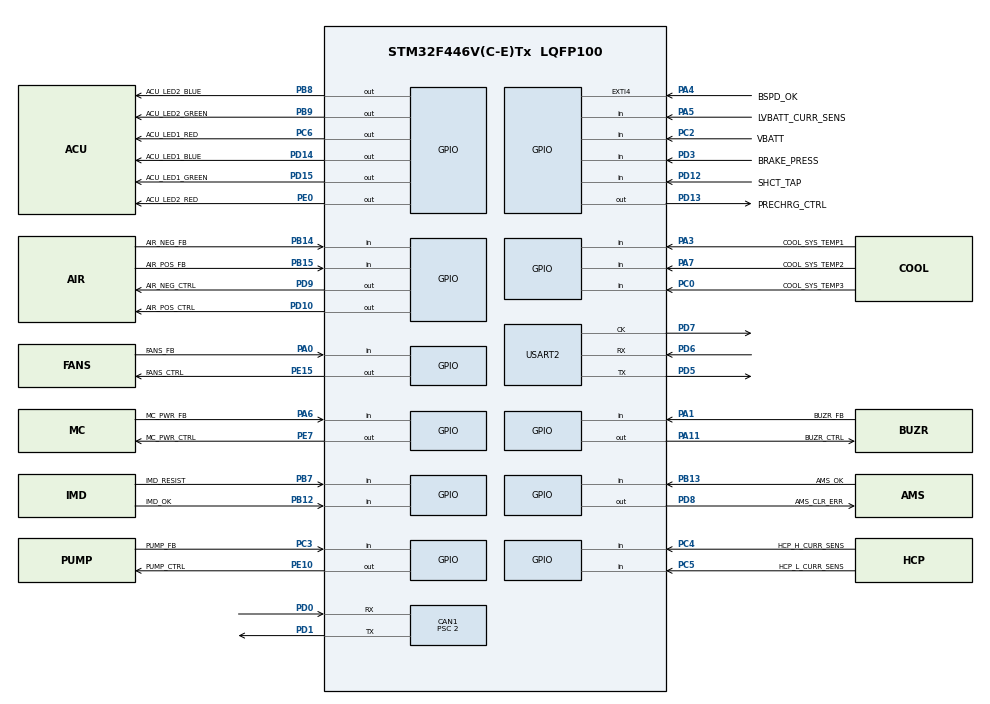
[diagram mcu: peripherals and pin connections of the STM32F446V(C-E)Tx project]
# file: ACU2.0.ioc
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CAN1.BS1=CAN_BS1_13TQ
CAN1.BS2=CAN_BS2_2TQ
CAN1.CalculateBaudRate=500000
CAN1.CalculateTimeBit=2000
CAN1.CalculateTimeQuantum=125.0
CAN1.Prescaler=2
FREERTOS.Events01=iwdgEventGroup,Dynamic,NULL
FREERTOS.INCLUDE_xTaskGetHandle=1
FREERTOS.Queues01=canRxPacketQueue,32,CAN_RxPacketTypeDef,0,Dynamic,NULL,NULL;canTxPacketQueue,32,CAN_TxPacketTypeDef,0,Dynamic,NULL,NULL;setCarStateQueue,32,uint8_t,0,Dynamic,NULL,NULL;bmsRxCanMsgQueue,16,CAN_RxPacketTypeDef,0,Dynamic,NULL,NULL;vcuCanCommsQueue,16,CAN_RxPacketTypeDef,0,Dynamic,NULL,NULL
FREERTOS.Tasks01=defaultTask,24,128,StartDefaultTask,Default,DEFAULT_TASK_ENABLED,Dynamic,NULL,NULL;acuStateTask,24,512,StartAcuStateTask,As external,ACU_STATE_TASK_ENABLED,Dynamic,NULL,NULL;vcuHrtBeatTask,24,256,StartVcuHrtBeatTask,As external,VCU_HRTBEAT_TASK_ENABLED,Dynamic,NULL,NULL;canTxTask,24,512,StartCanTxTask,As external,CAN_TX_TASK_ENABLED,Dynamic,NULL,NULL;canRxTask,24,512,StartCanRxTask,As external,CAN_RX_TASK_ENABLED,Dynamic,NULL,NULL;coolingTask,24,256,StartCoolingTask,As external,COOLING_TASK_ENABLED,Dynamic,NULL,NULL;watchDogTask,24,256,StartWatchDogTask,As external,WATCH_DOG_TASK_ENABLED,Dynamic,NULL,NULL;DebugLEDTask,24,128,StartDebugLEDTask,As external,LED_TASK_ENABLED,Dynamic,NULL,NULL;bmsCanCommTask,24,512,StartBmsCanCommTask,As external,BMS_CAN_COMM_TASK_ENABLED,Dynamic,NULL,NULL;vcuCanCommsTask,24,128,StartVcuCanCommsTask,As external,VCU_CAN_COMMS_TASK_ENABLED,Dynamic,NULL,NULL;bmsHrtbeatTask,24,256,StartBmsHeartbeatTask,As external,BMS_HRTBEAT_TASK_ENABLED,Dynamic,NULL,NULL
FREERTOS.configTOTAL_HEAP_SIZE=20000
FREERTOS.configUSE_NEWLIB_REENTRANT=1
IWDG.Prescaler=IWDG_PRESCALER_256
IWDG.Reload=IWDG_RELOAD_PERIOD
Mcu.Family=STM32F4
Mcu.Name=STM32F446V(C-E)Tx
Mcu.Package=LQFP100
Mcu.UserConstants=CAN_TX_TASK_ENABLED,1;VCU_CAN_COMMS_TASK_ENABLED,1;IWDG_RELOAD_PERIOD,4094;COOLING_TASK_ENABLED,0;VCU_HRTBEAT_TASK_ENABLED,1;LED_TASK_ENABLED,1;IWDG_EVENT_ALL_ALLOWED_BITS,0xFFFFFF;BMS_CAN_COMM_TASK_ENABLED,1;ACU_STATE_TASK_ENABLED,1;CAN_RX_TASK_ENABLED,1;DEFAULT_TASK_ENABLED,0;WATCH_DOG_TASK_ENABLED,1;BMS_HRTBEAT_TASK_ENABLED,1
NVIC.CAN1_RX0_IRQn=true\:5\:0\:false\:false\:true\:true\:true\:true\:true
NVIC.CAN1_SCE_IRQn=true\:5\:0\:false\:false\:true\:true\:true\:true\:true
NVIC.PriorityGroup=NVIC_PRIORITYGROUP_4
NVIC.TIM1_UP_TIM10_IRQn=true\:15\:0\:false\:false\:true\:false\:false\:true\:true
NVIC.TimeBase=TIM1_UP_TIM10_IRQn
NVIC.TimeBaseIP=TIM10
PA0-WKUP.GPIO_Label=FANS_FB
PA0-WKUP.Signal=GPIO_Input
PA1.GPIO_Label=BUZR_FB
PA1.Signal=GPIO_Input
PA11.GPIO_Label=BUZR_CTRL
PA11.Signal=GPIO_Output
PA13.Mode=Serial_Wire
PA13.Signal=SYS_JTMS-SWDIO
PA14.Mode=Serial_Wire
PA14.Signal=SYS_JTCK-SWCLK
PA3.GPIO_Label=COOL_SYS_TEMP1
PA3.Signal=GPIO_Input
PA4.GPIO_Label=BSPD_OK
PA4.Signal=GPXTI4
PA5.GPIO_Label=LVBATT_CURR_SENS
PA5.Signal=GPIO_Input
PA6.GPIO_Label=MC_PWR_FB
PA6.Signal=GPIO_Input
PA7.GPIO_Label=COOL_SYS_TEMP2
PA7.Signal=GPIO_Input
PB12.GPIO_Label=IMD_OK
PB12.Signal=GPIO_Input
PB13.GPIO_Label=AMS_OK
PB13.Signal=GPIO_Input
PB14.GPIO_Label=AIR_NEG_FB
PB14.Signal=GPIO_Input
PB15.GPIO_Label=AIR_POS_FB
PB15.Signal=GPIO_Input
PB7.GPIO_Label=IMD_RESIST
PB7.Signal=GPIO_Input
PB8.GPIO_Label=ACU_LED2_BLUE
PB8.Signal=GPIO_Output
PB9.GPIO_Label=ACU_LED2_GREEN
PB9.Signal=GPIO_Output
PC0.GPIO_Label=COOL_SYS_TEMP3
PC0.Signal=GPIO_Input
PC2.GPIO_Label=VBATT
PC2.Signal=GPIO_Input
PC3.GPIO_Label=PUMP_FB
PC3.Signal=GPIO_Input
PC4.GPIO_Label=HCP_H_CURR_SENS
PC4.Signal=GPIO_Input
PC5.GPIO_Label=HCP_L_CURR_SENS
PC5.Signal=GPIO_Input
PC6.GPIO_Label=ACU_LED1_RED
PC6.Signal=GPIO_Output
PD0.Mode=CAN_Activate
PD0.Signal=CAN1_RX
PD1.Mode=CAN_Activate
PD1.Signal=CAN1_TX
PD10.GPIO_Label=AIR_POS_CTRL
PD10.Signal=GPIO_Output
PD12.GPIO_Label=SHCT_TAP
PD12.Signal=GPIO_Input
PD13.GPIO_Label=PRECHRG_CTRL
PD13.Signal=GPIO_Output
PD14.GPIO_Label=ACU_LED1_BLUE
PD14.Signal=GPIO_Output
PD15.GPIO_Label=ACU_LED1_GREEN
PD15.Signal=GPIO_Output
PD3.GPIO_Label=BRAKE_PRESS
PD3.Signal=GPIO_Input
PD5.Mode=Synchronous
PD5.Signal=USART2_TX
PD6.Mode=Synchronous
PD6.Signal=USART2_RX
PD7.Mode=Synchronous
PD7.Signal=USART2_CK
PD8.GPIO_Label=AMS_CLR_ERR
PD8.Signal=GPIO_Output
PD9.GPIO_Label=AIR_NEG_CTRL
PD9.Signal=GPIO_Output
PE0.GPIO_Label=ACU_LED2_RED
PE0.Signal=GPIO_Output
PE10.GPIO_Label=PUMP_CTRL
PE10.Signal=GPIO_Output
PE15.GPIO_Label=FANS_CTRL
PE15.Signal=GPIO_Output
PE7.GPIO_Label=MC_PWR_CTRL
PE7.Signal=GPIO_Output
ProjectManager.HeapSize=0x200
ProjectManager.StackSize=0x400
ProjectManager.TargetToolchain=STM32CubeIDE
RCC.CortexFreq_Value=16000000
RCC.USBFreq_Value=96000000
RCC.VCOOutputFreq_Value=192000000
USART2.VirtualMode=VM_SYNC
VP_FREERTOS_VS_CMSIS_V2.Mode=CMSIS_V2
VP_IWDG_VS_IWDG.Mode=IWDG_Activate
VP_SYS_VS_tim10.Mode=TIM10
board=custom

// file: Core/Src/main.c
/* USER CODE BEGIN Header */
/**
  ******************************************************************************
  * @file           : main.c
  * @brief          : Main program body
  ******************************************************************************
  * @attention
  *
  * Copyright (c) 2024 STMicroelectronics.
  * All rights reserved.
  *
  * This software is licensed under terms that can be found in the LICENSE file
  * in the root directory of this software component.
  * If no LICENSE file comes with this software, it is provided AS-IS.
  *
  ******************************************************************************
  */
/* USER CODE END Header */
#include "main.h"
#include "cmsis_os.h"
#include "can.h"
#include "usart.h"
#include "gpio.h"

void SystemClock_Config(void);
void MX_FREERTOS_Init(void);

int main(void)
{

  /* MCU Configuration--------------------------------------------------------*/

  /* Reset of all peripherals, Initializes the Flash interface and the Systick. */
  HAL_Init();

  /* Configure the system clock */
  SystemClock_Config();

  /* Initialize all configured peripherals */
  MX_GPIO_Init();
  MX_CAN1_Init();
  MX_USART2_Init();
  /* USER CODE BEGIN 2 */
  HAL_GPIO_WritePin(MC_PWR_CTRL_GPIO_Port, MC_PWR_CTRL_Pin, GPIO_PIN_SET);
  HAL_Delay(500);
  /* USER CODE END 2 */

  /* Init scheduler */
  osKernelInitialize();

  /* Call init function for freertos objects (in cmsis_os2.c) */
  MX_FREERTOS_Init();

  /* Start scheduler */
  osKernelStart();

  /* We should never get here as control is now taken by the scheduler */

  /* Infinite loop */
  while (1)
  {

  }
}

void SystemClock_Config(void)
{
  RCC_OscInitTypeDef RCC_OscInitStruct = {0};
  RCC_ClkInitTypeDef RCC_ClkInitStruct = {0};

  /** Configure the main internal regulator output voltage
  */
  __HAL_RCC_PWR_CLK_ENABLE();
  __HAL_PWR_VOLTAGESCALING_CONFIG(PWR_REGULATOR_VOLTAGE_SCALE3);

  /** Initializes the RCC Oscillators according to the specified parameters
  * in the RCC_OscInitTypeDef structure.
  */
  RCC_OscInitStruct.OscillatorType = RCC_OSCILLATORTYPE_HSI|RCC_OSCILLATORTYPE_LSI;
  RCC_OscInitStruct.HSIState = RCC_HSI_ON;
  RCC_OscInitStruct.HSICalibrationValue = RCC_HSICALIBRATION_DEFAULT;
  RCC_OscInitStruct.LSIState = RCC_LSI_ON;
  RCC_OscInitStruct.PLL.PLLState = RCC_PLL_NONE;
  if (HAL_RCC_OscConfig(&RCC_OscInitStruct) != HAL_OK)
  {
    Error_Handler();
  }

  /** Initializes the CPU, AHB and APB buses clocks
  */
  RCC_ClkInitStruct.ClockType = RCC_CLOCKTYPE_HCLK|RCC_CLOCKTYPE_SYSCLK
                              |RCC_CLOCKTYPE_PCLK1|RCC_CLOCKTYPE_PCLK2;
  RCC_ClkInitStruct.SYSCLKSource = RCC_SYSCLKSOURCE_HSI;
  RCC_ClkInitStruct.AHBCLKDivider = RCC_SYSCLK_DIV1;
  RCC_ClkInitStruct.APB1CLKDivider = RCC_HCLK_DIV1;
  RCC_ClkInitStruct.APB2CLKDivider = RCC_HCLK_DIV1;

  if (HAL_RCC_ClockConfig(&RCC_ClkInitStruct, FLASH_LATENCY_0) != HAL_OK)
  {
    Error_Handler();
  }
}

void HAL_TIM_PeriodElapsedCallback(TIM_HandleTypeDef *htim)
{
  if (htim->Instance == TIM10) {
    HAL_IncTick();
  }
}

void Error_Handler(void)
{
}

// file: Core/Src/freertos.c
/* USER CODE BEGIN Header */
/**
  ******************************************************************************
  * File Name          : freertos.c
  * Description        : Code for freertos applications
  ******************************************************************************
  * @attention
  *
  * Copyright (c) 2024 STMicroelectronics.
  * All rights reserved.
  *
  * This software is licensed under terms that can be found in the LICENSE file
  * in the root directory of this software component.
  * If no LICENSE file comes with this software, it is provided AS-IS.
  *
  ******************************************************************************
  */
/* USER CODE END Header */

#include "FreeRTOS.h"
#include "task.h"
#include "main.h"
#include "cmsis_os.h"

/* USER CODE BEGIN Includes */
#include "can_utils.h"
#include "iwdg.h"
#include "car_state.h"
#include "heartbeat.h"
/* USER CODE END Includes */

/* Definitions for defaultTask */
osThreadId_t defaultTaskHandle;
const osThreadAttr_t defaultTask_attributes = {
  .name = "defaultTask",
  .stack_size = 128 * 4,
  .priority = (osPriority_t) osPriorityNormal,
};
/* Definitions for acuStateTask */
osThreadId_t acuStateTaskHandle;
const osThreadAttr_t acuStateTask_attributes = {
  .name = "acuStateTask",
  .stack_size = 512 * 4,
  .priority = (osPriority_t) osPriorityNormal,
};
/* Definitions for vcuHrtBeatTask */
osThreadId_t vcuHrtBeatTaskHandle;
const osThreadAttr_t vcuHrtBeatTask_attributes = {
  .name = "vcuHrtBeatTask",
  .stack_size = 256 * 4,
  .priority = (osPriority_t) osPriorityNormal,
};
/* Definitions for canTxTask */
osThreadId_t canTxTaskHandle;
const osThreadAttr_t canTxTask_attributes = {
  .name = "canTxTask",
  .stack_size = 512 * 4,
  .priority = (osPriority_t) osPriorityNormal,
};
/* Definitions for canRxTask */
osThreadId_t canRxTaskHandle;
const osThreadAttr_t canRxTask_attributes = {
  .name = "canRxTask",
  .stack_size = 512 * 4,
  .priority = (osPriority_t) osPriorityNormal,
};
/* Definitions for coolingTask */
osThreadId_t coolingTaskHandle;
const osThreadAttr_t coolingTask_attributes = {
  .name = "coolingTask",
  .stack_size = 256 * 4,
  .priority = (osPriority_t) osPriorityHigh,
};
/* Definitions for watchDogTask */
osThreadId_t watchDogTaskHandle;
const osThreadAttr_t watchDogTask_attributes = {
  .name = "watchDogTask",
  .stack_size = 256 * 4,
  .priority = (osPriority_t) osPriorityNormal,
};
/* Definitions for DebugLEDTask */
osThreadId_t DebugLEDTaskHandle;
const osThreadAttr_t DebugLEDTask_attributes = {
  .name = "DebugLEDTask",
  .stack_size = 128 * 4,
  .priority = (osPriority_t) osPriorityNormal,
};
/* Definitions for bmsCanCommTask */
osThreadId_t bmsCanCommTaskHandle;
const osThreadAttr_t bmsCanCommTask_attributes = {
  .name = "bmsCanCommTask",
  .stack_size = 512 * 4,
  .priority = (osPriority_t) osPriorityNormal,
};
/* Definitions for vcuCanCommsTask */
osThreadId_t vcuCanCommsTaskHandle;
const osThreadAttr_t vcuCanCommsTask_attributes = {
  .name = "vcuCanCommsTask",
  .stack_size = 128 * 4,
  .priority = (osPriority_t) osPriorityNormal,
};
/* Definitions for canRxPacketQueue */
osMessageQueueId_t canRxPacketQueueHandle;
const osMessageQueueAttr_t canRxPacketQueue_attributes = {
  .name = "canRxPacketQueue"
};
/* Definitions for canTxPacketQueue */
osMessageQueueId_t canTxPacketQueueHandle;
const osMessageQueueAttr_t canTxPacketQueue_attributes = {
  .name = "canTxPacketQueue"
};
/* Definitions for setCarStateQueue */
osMessageQueueId_t setCarStateQueueHandle;
const osMessageQueueAttr_t setCarStateQueue_attributes = {
  .name = "setCarStateQueue"
};
/* Definitions for bmsRxCanMsgQueue */
osMessageQueueId_t bmsRxCanMsgQueueHandle;
const osMessageQueueAttr_t bmsRxCanMsgQueue_attributes = {
  .name = "bmsRxCanMsgQueue"
};
/* Definitions for vcuCanCommsQueue */
osMessageQueueId_t vcuCanCommsQueueHandle;
const osMessageQueueAttr_t vcuCanCommsQueue_attributes = {
  .name = "vcuCanCommsQueue"
};
/* Definitions for iwdgEventGroup */
osEventFlagsId_t iwdgEventGroupHandle;
const osEventFlagsAttr_t iwdgEventGroup_attributes = {
  .name = "iwdgEventGroup"
};

void StartDefaultTask(void *argument);
extern void StartAcuStateTask(void *argument);
extern void StartVcuHrtBeatTask(void *argument);
extern void StartCanTxTask(void *argument);
extern void StartCanRxTask(void *argument);
extern void StartCoolingTask(void *argument);
extern void StartWatchDogTask(void *argument);
extern void StartDebugLEDTask(void *argument);
extern void StartBmsCanCommTask(void *argument);
extern void StartVcuCanCommsTask(void *argument);

void MX_FREERTOS_Init(void); /* (MISRA C 2004 rule 8.1) */

void MX_FREERTOS_Init(void) {
  /* USER CODE BEGIN Init */
  car_state_init();
  heartbeat_init();
  /* USER CODE END Init */

  /* Create the queue(s) */
  /* creation of canRxPacketQueue */
  canRxPacketQueueHandle = osMessageQueueNew (32, sizeof(CAN_RxPacketTypeDef), &canRxPacketQueue_attributes);

  /* creation of canTxPacketQueue */
  canTxPacketQueueHandle = osMessageQueueNew (32, sizeof(CAN_TxPacketTypeDef), &canTxPacketQueue_attributes);

  /* creation of setCarStateQueue */
  setCarStateQueueHandle = osMessageQueueNew (32, sizeof(uint8_t), &setCarStateQueue_attributes);

  /* creation of bmsRxCanMsgQueue */
  bmsRxCanMsgQueueHandle = osMessageQueueNew (16, sizeof(CAN_RxPacketTypeDef), &bmsRxCanMsgQueue_attributes);

  /* creation of vcuCanCommsQueue */
  vcuCanCommsQueueHandle = osMessageQueueNew (16, sizeof(CAN_RxPacketTypeDef), &vcuCanCommsQueue_attributes);

  /* Create the thread(s) */
  /* creation of defaultTask */
  defaultTaskHandle = osThreadNew(StartDefaultTask, (void*) DEFAULT_TASK_ENABLED, &defaultTask_attributes);

  /* creation of acuStateTask */
  acuStateTaskHandle = osThreadNew(StartAcuStateTask, (void*) ACU_STATE_TASK_ENABLED, &acuStateTask_attributes);

  /* creation of vcuHrtBeatTask */
  vcuHrtBeatTaskHandle = osThreadNew(StartVcuHrtBeatTask, (void*) VCU_HRTBEAT_TASK_ENABLED, &vcuHrtBeatTask_attributes);

  /* creation of canTxTask */
  canTxTaskHandle = osThreadNew(StartCanTxTask, (void*) CAN_TX_TASK_ENABLED, &canTxTask_attributes);

  /* creation of canRxTask */
  canRxTaskHandle = osThreadNew(StartCanRxTask, (void*) CAN_RX_TASK_ENABLED, &canRxTask_attributes);

  /* creation of coolingTask */
  coolingTaskHandle = osThreadNew(StartCoolingTask, (void*) COOLING_TASK_ENABLED, &coolingTask_attributes);

  /* creation of watchDogTask */
  watchDogTaskHandle = osThreadNew(StartWatchDogTask, (void*) WATCH_DOG_TASK_ENABLED, &watchDogTask_attributes);

  /* creation of DebugLEDTask */
  DebugLEDTaskHandle = osThreadNew(StartDebugLEDTask, (void*) LED_TASK_ENABLED, &DebugLEDTask_attributes);

  /* creation of bmsCanCommTask */
  bmsCanCommTaskHandle = osThreadNew(StartBmsCanCommTask, (void*) BMS_CAN_COMM_TASK_ENABLED, &bmsCanCommTask_attributes);

  /* creation of vcuCanCommsTask */
  vcuCanCommsTaskHandle = osThreadNew(StartVcuCanCommsTask, (void*) VCU_CAN_COMMS_TASK_ENABLED, &vcuCanCommsTask_attributes);

  /* Create the event(s) */
  /* creation of iwdgEventGroup */
  iwdgEventGroupHandle = osEventFlagsNew(&iwdgEventGroup_attributes);

}

void StartDefaultTask(void *argument)
{
  /* USER CODE BEGIN StartDefaultTask */
    uint8_t isTaskActivated = (int)argument;
    if (isTaskActivated == 0) {
        osThreadExit();
    }

  /* Infinite loop */
  for(;;)
  {
      kickWatchdogBit(osThreadGetId());
      osThreadYield();
  }
  /* USER CODE END StartDefaultTask */
}
